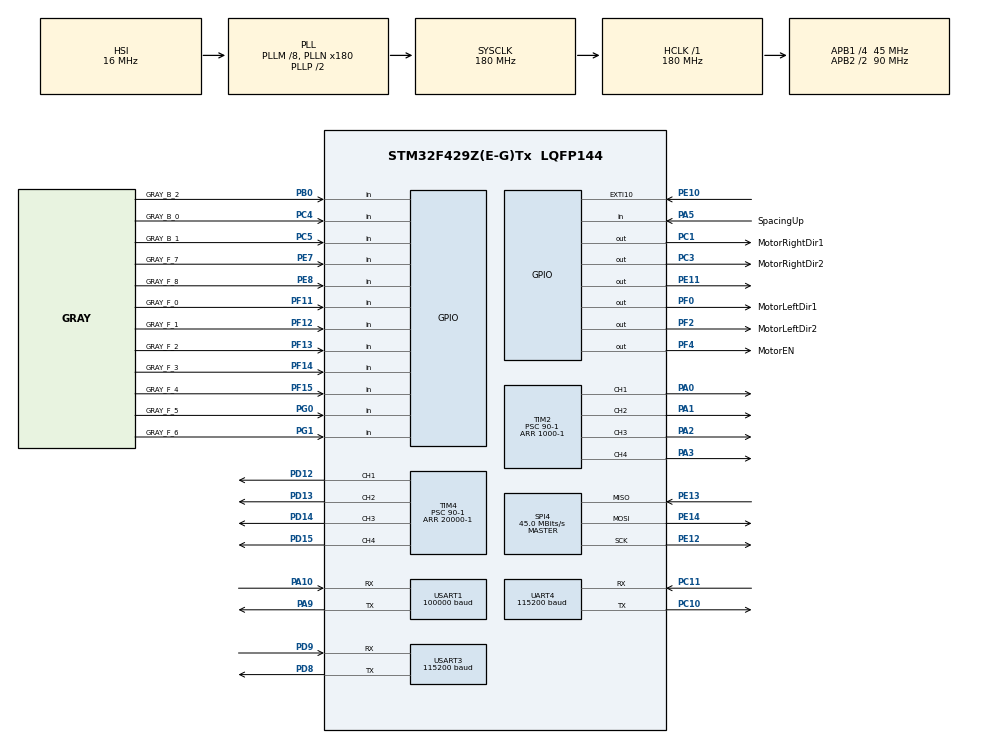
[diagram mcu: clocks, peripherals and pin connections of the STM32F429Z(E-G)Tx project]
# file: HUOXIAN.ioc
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Dma.Request0=USART3_RX
Dma.Request1=USART1_RX
Dma.USART1_RX.1.Direction=DMA_PERIPH_TO_MEMORY
Dma.USART1_RX.1.FIFOMode=DMA_FIFOMODE_DISABLE
Dma.USART1_RX.1.Instance=DMA2_Stream2
Dma.USART1_RX.1.MemDataAlignment=DMA_MDATAALIGN_BYTE
Dma.USART1_RX.1.MemInc=DMA_MINC_ENABLE
Dma.USART1_RX.1.Mode=DMA_NORMAL
Dma.USART1_RX.1.PeriphDataAlignment=DMA_PDATAALIGN_BYTE
Dma.USART1_RX.1.PeriphInc=DMA_PINC_DISABLE
Dma.USART1_RX.1.Priority=DMA_PRIORITY_LOW
Dma.USART3_RX.0.Direction=DMA_PERIPH_TO_MEMORY
Dma.USART3_RX.0.FIFOMode=DMA_FIFOMODE_DISABLE
Dma.USART3_RX.0.Instance=DMA1_Stream1
Dma.USART3_RX.0.MemDataAlignment=DMA_MDATAALIGN_BYTE
Dma.USART3_RX.0.MemInc=DMA_MINC_ENABLE
Dma.USART3_RX.0.Mode=DMA_NORMAL
Dma.USART3_RX.0.PeriphDataAlignment=DMA_PDATAALIGN_BYTE
Dma.USART3_RX.0.PeriphInc=DMA_PINC_DISABLE
Dma.USART3_RX.0.Priority=DMA_PRIORITY_LOW
FREERTOS.BinarySemaphores01=ImuIntSem,Dynamic,NULL
FREERTOS.Tasks01=OpenmvTask,24,128,OpenmvTask_Function,As weak,NULL,Dynamic,NULL,NULL;MoveTask,48,256,MoveTask_Function,As weak,NULL,Dynamic,NULL,NULL;ImuTask,8,256,ImuTask_Function,As weak,NULL,Dynamic,NULL,NULL;RunTask,40,128,RunTask_Function,As weak,NULL,Dynamic,NULL,NULL
Mcu.Family=STM32F4
Mcu.Name=STM32F429Z(E-G)Tx
Mcu.Package=LQFP144
NVIC.DMA1_Stream1_IRQn=true\:5\:0\:false\:false\:true\:true\:false\:true\:true
NVIC.DMA2_Stream2_IRQn=true\:5\:0\:false\:false\:true\:true\:false\:true\:true
NVIC.EXTI15_10_IRQn=true\:5\:0\:false\:false\:true\:true\:true\:true\:true
NVIC.PriorityGroup=NVIC_PRIORITYGROUP_4
NVIC.TIM7_IRQn=true\:5\:0\:false\:false\:true\:true\:true\:true\:true
NVIC.TIM8_UP_TIM13_IRQn=true\:15\:0\:false\:false\:true\:false\:false\:true\:true
NVIC.TimeBase=TIM8_UP_TIM13_IRQn
NVIC.TimeBaseIP=TIM8
NVIC.USART1_IRQn=true\:5\:0\:false\:false\:true\:true\:true\:true\:true
NVIC.USART3_IRQn=true\:5\:0\:false\:false\:true\:true\:true\:true\:true
PA0/WKUP.Signal=S_TIM2_CH1_ETR
PA1.Signal=S_TIM2_CH2
PA10.Mode=Asynchronous
PA10.Signal=USART1_RX
PA13.Mode=Serial_Wire
PA13.Signal=SYS_JTMS-SWDIO
PA14.Mode=Serial_Wire
PA14.Signal=SYS_JTCK-SWCLK
PA2.Signal=S_TIM2_CH3
PA3.Signal=S_TIM2_CH4
PA5.GPIO_Label=SpacingUp
PA5.GPIO_PuPd=GPIO_PULLUP
PA5.Signal=GPIO_Input
PA9.Mode=Asynchronous
PA9.Signal=USART1_TX
PB0.GPIO_Label=GRAY_B_2
PB0.GPIO_PuPd=GPIO_NOPULL
PB0.Signal=GPIO_Input
PC1.GPIO_Label=MotorRightDir1
PC1.Signal=GPIO_Output
PC10.Mode=Asynchronous
PC10.Signal=UART4_TX
PC11.Mode=Asynchronous
PC11.Signal=UART4_RX
PC3.GPIO_Label=MotorRightDir2
PC3.Signal=GPIO_Output
PC4.GPIO_Label=GRAY_B_0
PC4.Signal=GPIO_Input
PC5.GPIO_Label=GRAY_B_1
PC5.Signal=GPIO_Input
PD12.Signal=S_TIM4_CH1
PD13.Signal=S_TIM4_CH2
PD14.Signal=S_TIM4_CH3
PD15.Signal=S_TIM4_CH4
PD8.Mode=Asynchronous
PD8.Signal=USART3_TX
PD9.Mode=Asynchronous
PD9.Signal=USART3_RX
PE10.Signal=GPXTI10
PE11.Signal=GPIO_Output
PE12.Mode=Full_Duplex_Master
PE12.Signal=SPI4_SCK
PE13.Mode=Full_Duplex_Master
PE13.Signal=SPI4_MISO
PE14.Mode=Full_Duplex_Master
PE14.Signal=SPI4_MOSI
PE7.GPIO_Label=GRAY_F_7
PE7.Signal=GPIO_Input
PE8.GPIO_Label=GRAY_F_8
PE8.Signal=GPIO_Input
PF0.GPIO_Label=MotorLeftDir1
PF0.GPIO_Speed=GPIO_SPEED_FREQ_LOW
PF0.Signal=GPIO_Output
PF11.GPIO_Label=GRAY_F_0
PF11.Signal=GPIO_Input
PF12.GPIO_Label=GRAY_F_1
PF12.Signal=GPIO_Input
PF13.GPIO_Label=GRAY_F_2
PF13.Signal=GPIO_Input
PF14.GPIO_Label=GRAY_F_3
PF14.Signal=GPIO_Input
PF15.GPIO_Label=GRAY_F_4
PF15.Signal=GPIO_Input
PF2.GPIO_Label=MotorLeftDir2
PF2.Signal=GPIO_Output
PF4.GPIO_Label=MotorEN
PF4.Signal=GPIO_Output
PG0.GPIO_Label=GRAY_F_5
PG0.Signal=GPIO_Input
PG1.GPIO_Label=GRAY_F_6
PG1.Signal=GPIO_Input
PH0/OSC_IN.Mode=HSE-External-Oscillator
PH0/OSC_IN.Signal=RCC_OSC_IN
PH1/OSC_OUT.Mode=HSE-External-Oscillator
PH1/OSC_OUT.Signal=RCC_OSC_OUT
ProjectManager.HeapSize=0x200
ProjectManager.StackSize=0x400
ProjectManager.TargetToolchain=MDK-ARM V5.32
RCC.48MHZClocksFreq_Value=90000000
RCC.AHBFreq_Value=180000000
RCC.APB1CLKDivider=RCC_HCLK_DIV4
RCC.APB1Freq_Value=45000000
RCC.APB1TimFreq_Value=90000000
RCC.APB2CLKDivider=RCC_HCLK_DIV2
RCC.APB2Freq_Value=90000000
RCC.APB2TimFreq_Value=180000000
RCC.CortexFreq_Value=180000000
RCC.FLatency=FLASH_LATENCY_5
RCC.HCLKFreq_Value=180000000
RCC.HSE_VALUE=25000000
RCC.HSI_VALUE=16000000
RCC.LSE_VALUE=32768
RCC.PLLM=8
RCC.PLLN=180
RCC.PWREXT_OverDrive=PWREXT_OverDrive_ACTIVATED
RCC.PWR_Regulator_Voltage_Scale=PWR_REGULATOR_VOLTAGE_SCALE1
RCC.SYSCLKFreq_VALUE=180000000
RCC.SYSCLKSource=RCC_SYSCLKSOURCE_PLLCLK
RCC.VCOOutputFreq_Value=360000000
SH.S_TIM2_CH1_ETR.0=TIM2_CH1,PWM Generation1 CH1
SH.S_TIM2_CH2.0=TIM2_CH2,PWM Generation2 CH2
SH.S_TIM2_CH3.0=TIM2_CH3,PWM Generation3 CH3
SH.S_TIM2_CH4.0=TIM2_CH4,PWM Generation4 CH4
SH.S_TIM4_CH1.0=TIM4_CH1,PWM Generation1 CH1
SH.S_TIM4_CH2.0=TIM4_CH2,PWM Generation2 CH2
SH.S_TIM4_CH3.0=TIM4_CH3,PWM Generation3 CH3
SH.S_TIM4_CH4.0=TIM4_CH4,PWM Generation4 CH4
SPI4.CalculateBaudRate=45.0 MBits/s
SPI4.Direction=SPI_DIRECTION_2LINES
SPI4.Mode=SPI_MODE_MASTER
SPI4.VirtualType=VM_MASTER
TIM2.AutoReloadPreload=TIM_AUTORELOAD_PRELOAD_DISABLE
TIM2.Channel-PWM\ Generation1\ CH1=TIM_CHANNEL_1
TIM2.Channel-PWM\ Generation2\ CH2=TIM_CHANNEL_2
TIM2.Channel-PWM\ Generation3\ CH3=TIM_CHANNEL_3
TIM2.Channel-PWM\ Generation4\ CH4=TIM_CHANNEL_4
TIM2.ClockDivision=TIM_CLOCKDIVISION_DIV1
TIM2.CounterMode=TIM_COUNTERMODE_UP
TIM2.OC1Preload_PWM=ENABLE
TIM2.OC2Preload_PWM=ENABLE
TIM2.OC3Preload_PWM=ENABLE
TIM2.OC4Preload_PWM=ENABLE
TIM2.OCFastMode_PWM-PWM\ Generation1\ CH1=TIM_OCFAST_DISABLE
TIM2.OCFastMode_PWM-PWM\ Generation2\ CH2=TIM_OCFAST_DISABLE
TIM2.OCFastMode_PWM-PWM\ Generation3\ CH3=TIM_OCFAST_DISABLE
TIM2.OCFastMode_PWM-PWM\ Generation4\ CH4=TIM_OCFAST_DISABLE
TIM2.OCMode_PWM-PWM\ Generation1\ CH1=TIM_OCMODE_PWM1
TIM2.OCMode_PWM-PWM\ Generation2\ CH2=TIM_OCMODE_PWM1
TIM2.OCMode_PWM-PWM\ Generation3\ CH3=TIM_OCMODE_PWM1
TIM2.OCMode_PWM-PWM\ Generation4\ CH4=TIM_OCMODE_PWM1
TIM2.OCPolarity_1=TIM_OCPOLARITY_HIGH
TIM2.OCPolarity_2=TIM_OCPOLARITY_HIGH
TIM2.OCPolarity_3=TIM_OCPOLARITY_HIGH
TIM2.OCPolarity_4=TIM_OCPOLARITY_HIGH
TIM2.Period=1000-1
TIM2.Prescaler=90-1
TIM2.Pulse-PWM\ Generation1\ CH1=0
TIM2.Pulse-PWM\ Generation2\ CH2=0
TIM2.Pulse-PWM\ Generation3\ CH3=0
TIM2.Pulse-PWM\ Generation4\ CH4=0
TIM2.TIM_MasterOutputTrigger=TIM_TRGO_RESET
TIM2.TIM_MasterSlaveMode=TIM_MASTERSLAVEMODE_DISABLE
TIM4.AutoReloadPreload=TIM_AUTORELOAD_PRELOAD_DISABLE
TIM4.Channel-PWM\ Generation1\ CH1=TIM_CHANNEL_1
TIM4.Channel-PWM\ Generation2\ CH2=TIM_CHANNEL_2
TIM4.Channel-PWM\ Generation3\ CH3=TIM_CHANNEL_3
TIM4.Channel-PWM\ Generation4\ CH4=TIM_CHANNEL_4
TIM4.ClockDivision=TIM_CLOCKDIVISION_DIV1
TIM4.CounterMode=TIM_COUNTERMODE_UP
TIM4.OC1Preload_PWM=ENABLE
TIM4.OC2Preload_PWM=ENABLE
TIM4.OC3Preload_PWM=ENABLE
TIM4.OC4Preload_PWM=ENABLE
TIM4.OCFastMode_PWM-PWM\ Generation1\ CH1=TIM_OCFAST_DISABLE
TIM4.OCFastMode_PWM-PWM\ Generation2\ CH2=TIM_OCFAST_DISABLE
TIM4.OCFastMode_PWM-PWM\ Generation3\ CH3=TIM_OCFAST_DISABLE
TIM4.OCFastMode_PWM-PWM\ Generation4\ CH4=TIM_OCFAST_DISABLE
TIM4.OCMode_PWM-PWM\ Generation1\ CH1=TIM_OCMODE_PWM1
TIM4.OCMode_PWM-PWM\ Generation2\ CH2=TIM_OCMODE_PWM1
TIM4.OCMode_PWM-PWM\ Generation3\ CH3=TIM_OCMODE_PWM1
TIM4.OCMode_PWM-PWM\ Generation4\ CH4=TIM_OCMODE_PWM1
TIM4.OCPolarity_1=TIM_OCPOLARITY_HIGH
TIM4.OCPolarity_2=TIM_OCPOLARITY_HIGH
TIM4.OCPolarity_3=TIM_OCPOLARITY_HIGH
TIM4.OCPolarity_4=TIM_OCPOLARITY_HIGH
TIM4.Period=20000-1
TIM4.Prescaler=90-1
TIM4.Pulse-PWM\ Generation1\ CH1=0
TIM4.Pulse-PWM\ Generation2\ CH2=0
TIM4.Pulse-PWM\ Generation3\ CH3=0
TIM4.Pulse-PWM\ Generation4\ CH4=0
TIM4.TIM_MasterOutputTrigger=TIM_TRGO_RESET
TIM4.TIM_MasterSlaveMode=TIM_MASTERSLAVEMODE_DISABLE
TIM7.AutoReloadPreload=TIM_AUTORELOAD_PRELOAD_DISABLE
TIM7.CounterMode=TIM_COUNTERMODE_UP
TIM7.Period=1000-1
TIM7.Prescaler=180-1
TIM7.TIM_MasterOutputTrigger=TIM_TRGO_RESET
UART4.BaudRate=115200
UART4.Mode=MODE_TX_RX
UART4.OverSampling=UART_OVERSAMPLING_16
UART4.Parity=PARITY_NONE
UART4.StopBits=UART_STOPBITS_1
UART4.VirtualMode=Asynchronous
UART4.WordLength=WORDLENGTH_8B
USART1.BaudRate=100000
USART1.VirtualMode=VM_ASYNC
USART1.WordLength=WORDLENGTH_9B
USART3.BaudRate=115200
USART3.Mode=MODE_TX_RX
USART3.OverSampling=UART_OVERSAMPLING_16
USART3.Parity=PARITY_NONE
USART3.StopBits=STOPBITS_1
USART3.VirtualMode=VM_ASYNC
USART3.WordLength=WORDLENGTH_8B
VP_FREERTOS_VS_CMSIS_V2.Mode=CMSIS_V2
VP_SYS_VS_tim8.Mode=TIM8
VP_TIM7_VS_ClockSourceINT.Mode=Enable_Timer
board=custom

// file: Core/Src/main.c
/* USER CODE BEGIN Header */
/**
 ******************************************************************************
 * @file           : main.c
 * @brief          : Main program body
 ******************************************************************************
 * @attention
 *
 * Copyright (c) 2023 STMicroelectronics.
 * All rights reserved.
 *
 * This software is licensed under terms that can be found in the LICENSE file
 * in the root directory of this software component.
 * If no LICENSE file comes with this software, it is provided AS-IS.
 *
 ******************************************************************************
 */
/* USER CODE END Header */
#include "main.h"
#include "cmsis_os.h"
#include "dma.h"
#include "spi.h"
#include "tim.h"
#include "usart.h"
#include "gpio.h"

void SystemClock_Config(void);
void MX_FREERTOS_Init(void);

int main(void)
{

  /* MCU Configuration--------------------------------------------------------*/

  /* Reset of all peripherals, Initializes the Flash interface and the Systick. */
  HAL_Init();

  /* Configure the system clock */
  SystemClock_Config();

  /* Initialize all configured peripherals */
  MX_GPIO_Init();
  MX_DMA_Init();
  MX_TIM2_Init();
  MX_TIM4_Init();
  MX_USART3_UART_Init();
  MX_TIM7_Init();
  MX_UART4_Init();
  MX_USART1_UART_Init();
  MX_SPI4_Init();
  /* USER CODE BEGIN 2 */
  OpenmvInit();
  mpu_device_init(); // 陀螺仪配置初始化
  init_quaternion(); // 四元数初始化
  MotorInit();
  ServoInit();

  /* USER CODE END 2 */

  /* Init scheduler */
  osKernelInitialize(); /* Call init function for freertos objects (in freertos.c) */
  MX_FREERTOS_Init();

  /* Start scheduler */
  osKernelStart();

  /* We should never get here as control is now taken by the scheduler */
  /* Infinite loop */
  while (1)
  {

  }
}

void SystemClock_Config(void)
{
  RCC_OscInitTypeDef RCC_OscInitStruct = {0};
  RCC_ClkInitTypeDef RCC_ClkInitStruct = {0};

  /** Configure the main internal regulator output voltage
   */
  __HAL_RCC_PWR_CLK_ENABLE();
  __HAL_PWR_VOLTAGESCALING_CONFIG(PWR_REGULATOR_VOLTAGE_SCALE1);

  /** Initializes the RCC Oscillators according to the specified parameters
   * in the RCC_OscInitTypeDef structure.
   */
  RCC_OscInitStruct.OscillatorType = RCC_OSCILLATORTYPE_HSI;
  RCC_OscInitStruct.HSIState = RCC_HSI_ON;
  RCC_OscInitStruct.HSICalibrationValue = RCC_HSICALIBRATION_DEFAULT;
  RCC_OscInitStruct.PLL.PLLState = RCC_PLL_ON;
  RCC_OscInitStruct.PLL.PLLSource = RCC_PLLSOURCE_HSI;
  RCC_OscInitStruct.PLL.PLLM = 8;
  RCC_OscInitStruct.PLL.PLLN = 180;
  RCC_OscInitStruct.PLL.PLLP = RCC_PLLP_DIV2;
  RCC_OscInitStruct.PLL.PLLQ = 4;
  if (HAL_RCC_OscConfig(&RCC_OscInitStruct) != HAL_OK)
  {
    Error_Handler();
  }

  /** Activate the Over-Drive mode
   */
  if (HAL_PWREx_EnableOverDrive() != HAL_OK)
  {
    Error_Handler();
  }

  /** Initializes the CPU, AHB and APB buses clocks
   */
  RCC_ClkInitStruct.ClockType = RCC_CLOCKTYPE_HCLK | RCC_CLOCKTYPE_SYSCLK | RCC_CLOCKTYPE_PCLK1 | RCC_CLOCKTYPE_PCLK2;
  RCC_ClkInitStruct.SYSCLKSource = RCC_SYSCLKSOURCE_PLLCLK;
  RCC_ClkInitStruct.AHBCLKDivider = RCC_SYSCLK_DIV1;
  RCC_ClkInitStruct.APB1CLKDivider = RCC_HCLK_DIV4;
  RCC_ClkInitStruct.APB2CLKDivider = RCC_HCLK_DIV2;

  if (HAL_RCC_ClockConfig(&RCC_ClkInitStruct, FLASH_LATENCY_5) != HAL_OK)
  {
    Error_Handler();
  }
}

void HAL_TIM_PeriodElapsedCallback(TIM_HandleTypeDef *htim)
{
  if (htim->Instance == TIM8)
  {
    HAL_IncTick();
  }
}

void Error_Handler(void)
{
  __disable_irq();
  while (1)
  {
  }
}

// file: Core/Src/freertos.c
/* USER CODE BEGIN Header */
/**
  ******************************************************************************
  * File Name          : freertos.c
  * Description        : Code for freertos applications
  ******************************************************************************
  * @attention
  *
  * Copyright (c) 2023 STMicroelectronics.
  * All rights reserved.
  *
  * This software is licensed under terms that can be found in the LICENSE file
  * in the root directory of this software component.
  * If no LICENSE file comes with this software, it is provided AS-IS.
  *
  ******************************************************************************
  */
/* USER CODE END Header */

#include "FreeRTOS.h"
#include "task.h"
#include "main.h"
#include "cmsis_os.h"

/* Definitions for OpenmvTask */
osThreadId_t OpenmvTaskHandle;
const osThreadAttr_t OpenmvTask_attributes = {
  .name = "OpenmvTask",
  .stack_size = 128 * 4,
  .priority = (osPriority_t) osPriorityNormal,
};
/* Definitions for MoveTask */
osThreadId_t MoveTaskHandle;
const osThreadAttr_t MoveTask_attributes = {
  .name = "MoveTask",
  .stack_size = 256 * 4,
  .priority = (osPriority_t) osPriorityRealtime,
};
/* Definitions for ImuTask */
osThreadId_t ImuTaskHandle;
const osThreadAttr_t ImuTask_attributes = {
  .name = "ImuTask",
  .stack_size = 256 * 4,
  .priority = (osPriority_t) osPriorityLow,
};
/* Definitions for RunTask */
osThreadId_t RunTaskHandle;
const osThreadAttr_t RunTask_attributes = {
  .name = "RunTask",
  .stack_size = 128 * 4,
  .priority = (osPriority_t) osPriorityHigh,
};
/* Definitions for ImuIntSem */
osSemaphoreId_t ImuIntSemHandle;
const osSemaphoreAttr_t ImuIntSem_attributes = {
  .name = "ImuIntSem"
};

void OpenmvTask_Function(void *argument);
void MoveTask_Function(void *argument);
void ImuTask_Function(void *argument);
void RunTask_Function(void *argument);

void MX_FREERTOS_Init(void); /* (MISRA C 2004 rule 8.1) */

void MX_FREERTOS_Init(void) {

  /* Create the semaphores(s) */
  /* creation of ImuIntSem */
  ImuIntSemHandle = osSemaphoreNew(1, 1, &ImuIntSem_attributes);

  /* Create the thread(s) */
  /* creation of OpenmvTask */
  OpenmvTaskHandle = osThreadNew(OpenmvTask_Function, NULL, &OpenmvTask_attributes);

  /* creation of MoveTask */
  MoveTaskHandle = osThreadNew(MoveTask_Function, NULL, &MoveTask_attributes);

  /* creation of ImuTask */
  ImuTaskHandle = osThreadNew(ImuTask_Function, NULL, &ImuTask_attributes);

  /* creation of RunTask */
  RunTaskHandle = osThreadNew(RunTask_Function, NULL, &RunTask_attributes);

}

__weak void OpenmvTask_Function(void *argument)
{
  for(;;)
  {
    osDelay(1);
  }
}

__weak void MoveTask_Function(void *argument)
{
  for(;;)
  {
    osDelay(1);
  }
}

__weak void ImuTask_Function(void *argument)
{
  for(;;)
  {
    osDelay(1);
  }
}

__weak void RunTask_Function(void *argument)
{
  for(;;)
  {
    osDelay(1);
  }
}
